# STM32WBA25 register map
File version: 1.0
CPU: CM33 r0p1, little endian, MPU, FPU, 4 interrupt priority bits
Registers are 32-bit, read-write, reset 0x0 unless marked. A register's access mark holds for its fields unless they carry their own. Offsets are from the block's base; [hi:lo] are bit positions; {n}, {i} and the like mark numbered series; 'fields as' and 'values as' point back to an identical list.

## GPIOH — GPIOH address block description
Base 0x42021C00
Same registers: SEC_GPIOH 0x52021C00
0x00 GPIOH_MODER reset 0xC0 — GPIO port H mode register
  [7:6] MODE3 — Port H configuration I/O pin 3
    0=Input mode; 1=General purpose output mode; 2=Alternate function mode; 3=Analog mode (reset state)
0x04 GPIOH_OTYPER — GPIO port H output type register
  [3] OT3 — Port H configuration I/O pin 3
    0=Output push-pull (reset state); 1=Output open-drain
0x08 GPIOH_OSPEEDR — GPIO port H output speed register
  [7:6] OSPEED3 — Port H configuration I/O pin 3
    0=Low speed; 1=Medium speed; 2=High speed
0x0C GPIOH_PUPDR — GPIO port H pull-up/pull-down register
  [7:6] PUPD3 — Port H configuration I/O pin 3
    0=No pull-up, pull-down; 1=Pull-up; 2=Pull-down
0x10 GPIOH_IDR ro (reset mask 0xFFFF0000) — GPIO port H input data register
  [3] ID3 — Port H input data I/O pin 3
0x14 GPIOH_ODR — GPIO port H output data register
  [3] OD3 — Port H output data I/O pin 3
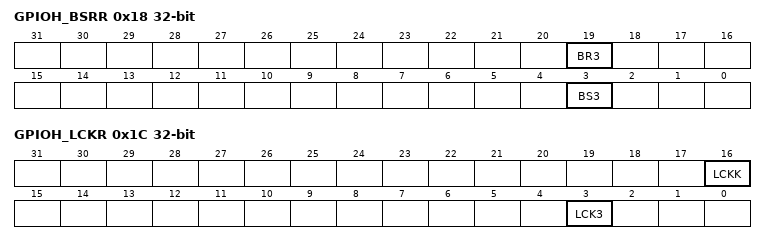
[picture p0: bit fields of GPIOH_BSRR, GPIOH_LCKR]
0x18 GPIOH_BSRR wo — GPIO port H bit set/reset register
  [19] BR3 — Port H reset I/O pin 3
    0=No action on the corresponding OD3 bit; 1=Resets the corresponding OD3 bit
  [3] BS3 — Port H set I/O pin 3
    0=No action on the corresponding OD3 bit; 1=Sets the corresponding OD3 bit
0x1C GPIOH_LCKR — GPIO port H configuration lock register
  [16] LCKK — Lock key
    0=Port configuration lock key not active; 1=Port configuration lock key active
  [3] LCK3 — Port H lock I/O pin 3
    0=Port configuration not locked; 1=Port configuration locked
0x20 GPIOH_AFRL — GPIO port H alternate function low register
  [15:12] AFSEL3 — Alternate function selection for port H I/O pin 3
    {v}=AF{v} (v=0..15)
0x28 GPIOH_BRR wo — GPIO port H bit reset register
  [3] BR3 — Port H reset I/O pin 3
    0=No action on the corresponding OD3 bit; 1=Reset the corresponding OD3 bit
0x30 GPIOH_SECCFGR wo reset 0xFFFF — GPIO port H secure configuration register
  [3] SEC3 — I/O pin of port H secure bit enable 3
    0=The I/O pin is non-secure; 1=The I/O pin is secure

## GTZC1_MPCBB1 — GTZC1_MPCBB1 address block description
Base 0x40032C00
Same registers: SEC_GTZC1_MPCBB1 0x50032C00
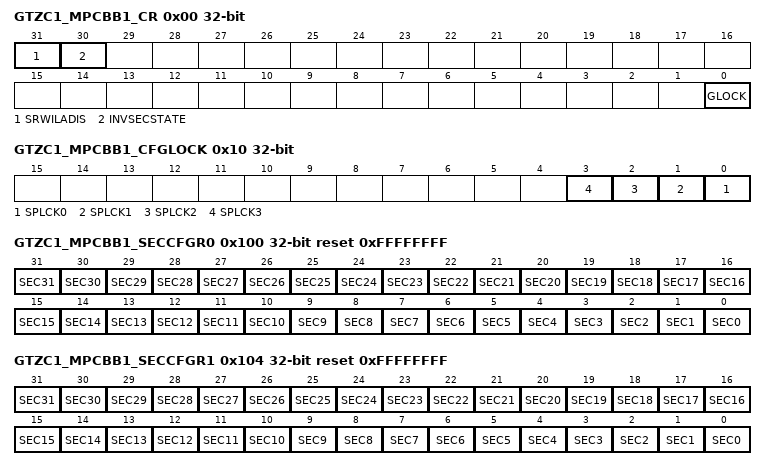
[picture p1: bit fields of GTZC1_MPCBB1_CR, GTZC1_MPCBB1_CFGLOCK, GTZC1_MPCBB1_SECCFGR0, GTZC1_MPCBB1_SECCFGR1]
0x00 GTZC1_MPCBB1_CR — GTZC1 MPCBB control register
  [31] SRWILADIS — secure read/write illegal access disable
    0=enabled, secure read/write acces not allowed on nonsecure SRAMx block; 1=disabled, secure read/write access allowed on nonsecure SRAMx block
  [30] INVSECSTATE — SRAM clocks security state
    0=SRAM clock is secured if a secure area exists in the MPCBBx; 1=SRAM clock is nonsecure even if a secure area exists in the MPCBBx, and secure even if no secure block is set in the MPCBBx
  [0] GLOCK — Lock the control register of the MPCBBx until next reset
    0=Control register not locked; 1=Control register locked
0x10 GTZC1_MPCBB1_CFGLOCK (alternate view of GTZC1_TZSC_SECCFGR1) — GTZC1 MPCBB1 configuration lock register
  [all] fields
    0=GTZC1_MPCBB1_SECCFGRn and GTZC1_MPCBB1_PRIVCFGRn can be written; 1=Writes to GTZC1_MPCBB1_SECCFGRn and GTZC1_MPCBB1_PRIVCFGRn are ignored
  [n] SPLCK{n} (n=0..3) — Security/privilege configuration lock super-block
0x100 GTZC1_MPCBB1_SECCFGR0 reset 0xFFFFFFFF — GTZC1 MPCBB security configuration for super-block 0 register
  [all] fields
    0=Nonsecure access only to block y, belonging to super-block n; 1=Secure access only to block y, belonging to super-block n
  [n] SEC{n} (n=0..31) — Security configuration for block y (y = 0 to 31) in super block n
0x104 GTZC1_MPCBB1_SECCFGR1 reset 0xFFFFFFFF — GTZC1 MPCBB security configuration for super-block 1 register
  fields as GTZC1_MPCBB1_SECCFGR0
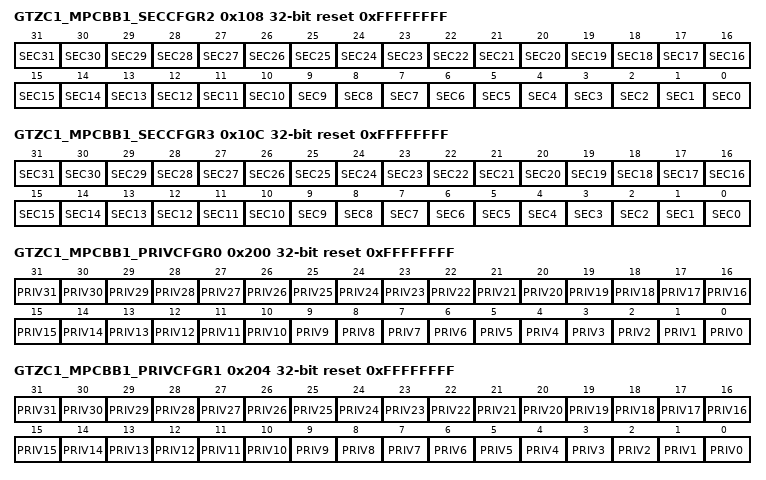
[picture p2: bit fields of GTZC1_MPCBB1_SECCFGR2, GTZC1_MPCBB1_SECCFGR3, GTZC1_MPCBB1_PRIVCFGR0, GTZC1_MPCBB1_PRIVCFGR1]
0x108 GTZC1_MPCBB1_SECCFGR2 reset 0xFFFFFFFF — GTZC1 MPCBB1 security configuration for super-block 2 register
  fields as GTZC1_MPCBB1_SECCFGR0
0x10C GTZC1_MPCBB1_SECCFGR3 reset 0xFFFFFFFF — GTZC1 MPCBB1 security configuration for super-block 3 register
  fields as GTZC1_MPCBB1_SECCFGR0
0x200 GTZC1_MPCBB1_PRIVCFGR0 reset 0xFFFFFFFF — GTZC1 MPCBB privileged configuration for super-block 0 register
  [all] fields
    0=Privileged and unprivileged access to block y, belonging to super-block n; 1=Only privileged access to block y, belonging to super-block n
  [n] PRIV{n} (n=0..31) — Privileged configuration for block y (y = 0 to 31), belonging to super-block n.
0x204 GTZC1_MPCBB1_PRIVCFGR1 reset 0xFFFFFFFF — GTZC1 MPCBB privileged configuration for super-block 1 register
  fields as GTZC1_MPCBB1_PRIVCFGR0
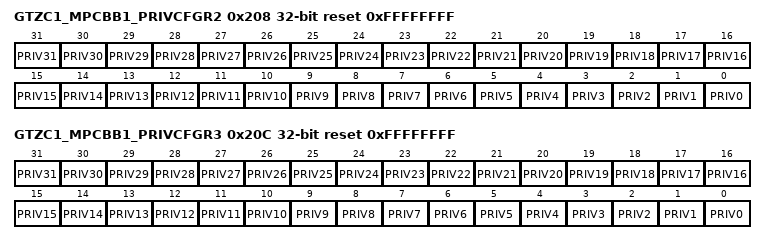
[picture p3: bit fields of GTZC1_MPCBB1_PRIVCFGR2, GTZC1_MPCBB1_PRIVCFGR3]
0x208 GTZC1_MPCBB1_PRIVCFGR2 reset 0xFFFFFFFF — GTZC1 MPCBB1 privileged configuration for super-block 2 register
  fields as GTZC1_MPCBB1_PRIVCFGR0
0x20C GTZC1_MPCBB1_PRIVCFGR3 reset 0xFFFFFFFF — GTZC1 MPCBB1 privileged configuration for super-block 3 register
  fields as GTZC1_MPCBB1_PRIVCFGR0

## GTZC1_MPCBB2 — GTZC1_MPCBB2 address block description
Base 0x40033000
Same registers: SEC_GTZC1_MPCBB2 0x50033000
Registers as GTZC1_MPCBB1 (with GTZC1_MPCBB1 read as GTZC1_MPCBB2), without GTZC1_MPCBB1_SECCFGR2, GTZC1_MPCBB1_SECCFGR3, GTZC1_MPCBB1_PRIVCFGR2, GTZC1_MPCBB1_PRIVCFGR3; these are added or differ:
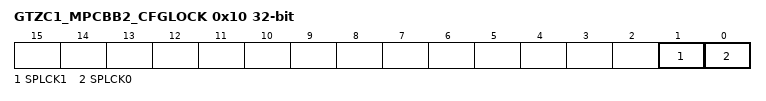
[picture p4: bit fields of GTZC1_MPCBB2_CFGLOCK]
0x10 GTZC1_MPCBB2_CFGLOCK (alternate view of GTZC1_TZSC_SECCFGR1) — GTZC1 MPCBB2 configuration lock register
  [1] SPLCK1 — Security/privilege configuration lock super-block
    0=GTZC1_MPCBB2_SECCFGRn and GTZC1_MPCBB2_PRIVCFGRn can be written; 1=Writes to GTZC1_MPCBB2_SECCFGRn and GTZC1_MPCBB2_PRIVCFGRn are ignored
  [0] SPLCK0 — Security/privilege configuration lock super-block
    values as SPLCK1
